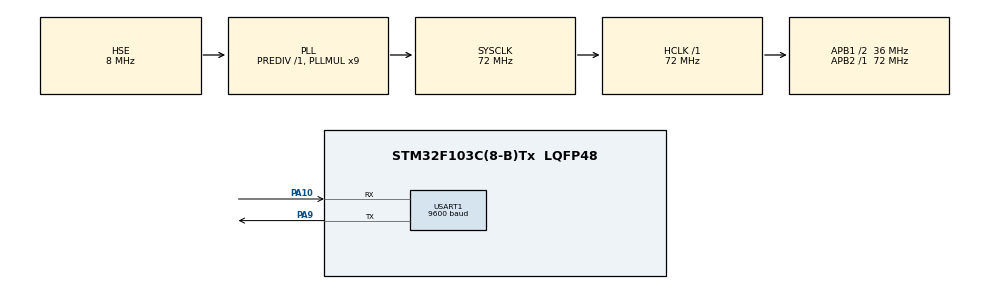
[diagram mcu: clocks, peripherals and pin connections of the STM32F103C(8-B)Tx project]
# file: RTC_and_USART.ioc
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Mcu.Family=STM32F1
Mcu.Name=STM32F103C(8-B)Tx
Mcu.Package=LQFP48
NVIC.PriorityGroup=NVIC_PRIORITYGROUP_4
NVIC.USART1_IRQn=true\:0\:0\:false\:false\:true\:true\:true\:true
PA10.Mode=Asynchronous
PA10.Signal=USART1_RX
PA13.Mode=Serial_Wire
PA13.Signal=SYS_JTMS-SWDIO
PA14.Mode=Serial_Wire
PA14.Signal=SYS_JTCK-SWCLK
PA9.Mode=Asynchronous
PA9.Signal=USART1_TX
PC14-OSC32_IN.Mode=LSE-External-Oscillator
PC14-OSC32_IN.Signal=RCC_OSC32_IN
PC15-OSC32_OUT.Mode=LSE-External-Oscillator
PC15-OSC32_OUT.Signal=RCC_OSC32_OUT
PD0-OSC_IN.Mode=HSE-External-Oscillator
PD0-OSC_IN.Signal=RCC_OSC_IN
PD1-OSC_OUT.Mode=HSE-External-Oscillator
PD1-OSC_OUT.Signal=RCC_OSC_OUT
ProjectManager.HeapSize=0x200
ProjectManager.StackSize=0x400
ProjectManager.TargetToolchain=MDK-ARM V5.32
RCC.AHBFreq_Value=72000000
RCC.APB1CLKDivider=RCC_HCLK_DIV2
RCC.APB1Freq_Value=36000000
RCC.APB1TimFreq_Value=72000000
RCC.APB2Freq_Value=72000000
RCC.APB2TimFreq_Value=72000000
RCC.HCLKFreq_Value=72000000
RCC.PLLMUL=RCC_PLL_MUL9
RCC.PLLSourceVirtual=RCC_PLLSOURCE_HSE
RCC.RTCClockSelection=RCC_RTCCLKSOURCE_LSE
RCC.SYSCLKFreq_VALUE=72000000
RCC.SYSCLKSource=RCC_SYSCLKSOURCE_PLLCLK
RCC.USBFreq_Value=72000000
USART1.BaudRate=9600
USART1.VirtualMode=VM_ASYNC
VP_RTC_VS_RTC_Activate.Mode=RTC_Enabled
VP_RTC_VS_RTC_Calendar.Mode=RTC_Calendar
board=custom

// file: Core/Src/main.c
/* USER CODE BEGIN Header */
#include <stdio.h>
/**
  ******************************************************************************
  * @file           : main.c
  * @brief          : Main program body
  ******************************************************************************
  * @attention
  *
  * Copyright (c) 2025 STMicroelectronics.
  * All rights reserved.
  *
  * This software is licensed under terms that can be found in the LICENSE file
  * in the root directory of this software component.
  * If no LICENSE file comes with this software, it is provided AS-IS.
  *
  ******************************************************************************
  */
/* USER CODE END Header */
#include "main.h"
#include "rtc.h"
#include "usart.h"
#include "gpio.h"

/* USER CODE BEGIN Includes */
char  RxBuffer[4];

RTC_TimeTypeDef mytime = {0};
uint8_t hour = 0;
uint8_t minute = 0;
uint8_t second = 0;
RTC_DateTypeDef mydate = {0};
uint8_t year = 0;
uint8_t month = 0;
uint8_t day = 0;
/* USER CODE END Includes */

/* USER CODE BEGIN PD */
void HAL_UART_RxCpltCallback(UART_HandleTypeDef *huart)
	{
		if(huart==&huart1)
		{
				if(RxBuffer[0]=='0')
				{
					if(RxBuffer[1]=='x')
					{
						if(RxBuffer[2]=='F')
						{
							if(RxBuffer[3]=='F')
							{
								printf("0xFF\r\n");
								HAL_RTC_GetTime(&hrtc,&mytime,RTC_FORMAT_BCD);
								HAL_RTC_GetDate(&hrtc,&mydate,RTC_FORMAT_BCD);

								hour=mytime.Hours;
								minute=mytime.Minutes;
								second=mytime.Seconds;
								year=mydate.Year;
								month=mydate.Month;
								day=mydate.Date;

								printf("现在是%d年%d月%d日%d时%d分%d秒\r\n",year,month,day,hour,minute,second);
							}
						}
					}
				 }
		}
		HAL_UART_Receive_IT(&huart1,(uint8_t *)RxBuffer,4);
	}
/* USER CODE END PD */

void SystemClock_Config(void);

int main(void)
{

  /* MCU Configuration--------------------------------------------------------*/

  /* Reset of all peripherals, Initializes the Flash interface and the Systick. */
  HAL_Init();

  /* Configure the system clock */
  SystemClock_Config();

  /* Initialize all configured peripherals */
  MX_GPIO_Init();
  MX_RTC_Init();
  MX_USART1_UART_Init();

  /* Infinite loop */
  /* USER CODE BEGIN WHILE */
	HAL_UART_Receive_IT(&huart1,(uint8_t *)RxBuffer,4);
  while (1)
  {
    /* USER CODE END WHILE */

  }
}

void SystemClock_Config(void)
{
  RCC_OscInitTypeDef RCC_OscInitStruct = {0};
  RCC_ClkInitTypeDef RCC_ClkInitStruct = {0};
  RCC_PeriphCLKInitTypeDef PeriphClkInit = {0};

  /** Initializes the RCC Oscillators according to the specified parameters
  * in the RCC_OscInitTypeDef structure.
  */
  RCC_OscInitStruct.OscillatorType = RCC_OSCILLATORTYPE_HSE|RCC_OSCILLATORTYPE_LSE;
  RCC_OscInitStruct.HSEState = RCC_HSE_ON;
  RCC_OscInitStruct.HSEPredivValue = RCC_HSE_PREDIV_DIV1;
  RCC_OscInitStruct.LSEState = RCC_LSE_ON;
  RCC_OscInitStruct.HSIState = RCC_HSI_ON;
  RCC_OscInitStruct.PLL.PLLState = RCC_PLL_ON;
  RCC_OscInitStruct.PLL.PLLSource = RCC_PLLSOURCE_HSE;
  RCC_OscInitStruct.PLL.PLLMUL = RCC_PLL_MUL9;
  if (HAL_RCC_OscConfig(&RCC_OscInitStruct) != HAL_OK)
  {
    Error_Handler();
  }

  /** Initializes the CPU, AHB and APB buses clocks
  */
  RCC_ClkInitStruct.ClockType = RCC_CLOCKTYPE_HCLK|RCC_CLOCKTYPE_SYSCLK
                              |RCC_CLOCKTYPE_PCLK1|RCC_CLOCKTYPE_PCLK2;
  RCC_ClkInitStruct.SYSCLKSource = RCC_SYSCLKSOURCE_PLLCLK;
  RCC_ClkInitStruct.AHBCLKDivider = RCC_SYSCLK_DIV1;
  RCC_ClkInitStruct.APB1CLKDivider = RCC_HCLK_DIV2;
  RCC_ClkInitStruct.APB2CLKDivider = RCC_HCLK_DIV1;

  if (HAL_RCC_ClockConfig(&RCC_ClkInitStruct, FLASH_LATENCY_2) != HAL_OK)
  {
    Error_Handler();
  }
  PeriphClkInit.PeriphClockSelection = RCC_PERIPHCLK_RTC;
  PeriphClkInit.RTCClockSelection = RCC_RTCCLKSOURCE_LSE;
  if (HAL_RCCEx_PeriphCLKConfig(&PeriphClkInit) != HAL_OK)
  {
    Error_Handler();
  }
}

void Error_Handler(void)
{
  __disable_irq();
  while (1)
  {
  }
}
